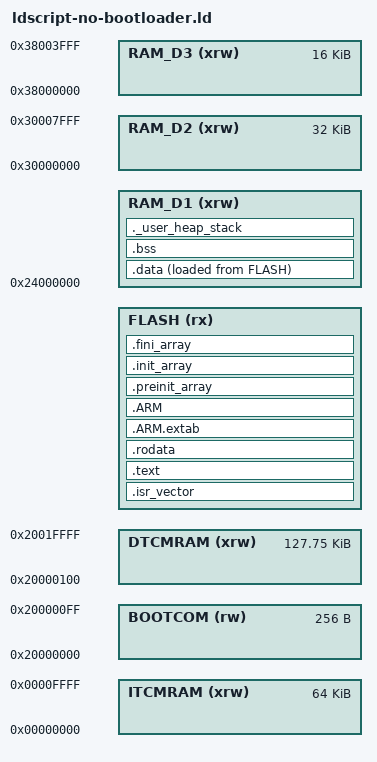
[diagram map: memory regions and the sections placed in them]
/*
******************************************************************************
**
**  Linker script for STM32H723ZGT6 (MicroNodePlus) -- standalone (no bootloader).
**
**  FLASH starts at 0x08000000 -- the application IS the only firmware on the
**  chip. BOOTCOM region (0x20000000, 256 B) is reserved in DTCMRAM so the
**  IPC layout matches the bootloader-aware build; an app linked here can be
**  re-built against `ldscript.ld` later without changing its source.
**
*****************************************************************************
*/

ENTRY(Reset_Handler)

_estack = ORIGIN(RAM_D1) + LENGTH(RAM_D1);
_Min_Heap_Size = 0x200;
_Min_Stack_Size = 0x400;

MEMORY
{
  ITCMRAM (xrw)    : ORIGIN = 0x00000000, LENGTH = 64K
  BOOTCOM (rw)     : ORIGIN = 0x20000000, LENGTH = 0x100
  DTCMRAM (xrw)    : ORIGIN = 0x20000100, LENGTH = 128K - 0x100
  FLASH    (rx)    : ORIGIN = 0x08000000 + LD_FLASH_OFFSET, LENGTH = LD_MAX_SIZE - LD_FLASH_OFFSET
  RAM_D1  (xrw)    : ORIGIN = 0x24000000, LENGTH = LD_MAX_DATA_SIZE
  RAM_D2  (xrw)    : ORIGIN = 0x30000000, LENGTH = 32K
  RAM_D3  (xrw)    : ORIGIN = 0x38000000, LENGTH = 16K
}

SECTIONS
{
  .isr_vector :
  {
    . = ALIGN(4);
    KEEP(*(.isr_vector))
    . = ALIGN(4);
  } >FLASH

  .text :
  {
    . = ALIGN(4);
    *(.text)
    *(.text*)
    *(.glue_7)
    *(.glue_7t)
    *(.eh_frame)

    KEEP (*(.init))
    KEEP (*(.fini))

    . = ALIGN(4);
    _etext = .;
  } >FLASH

  .rodata :
  {
    . = ALIGN(4);
    *(.rodata)
    *(.rodata*)
    . = ALIGN(4);
  } >FLASH

  .ARM.extab   : { *(.ARM.extab* .gnu.linkonce.armextab.*) } >FLASH
  .ARM (READONLY) : {
    __exidx_start = .;
    *(.ARM.exidx*)
    __exidx_end = .;
  } >FLASH

  .preinit_array (READONLY) :
  {
    PROVIDE_HIDDEN (__preinit_array_start = .);
    KEEP (*(.preinit_array*))
    PROVIDE_HIDDEN (__preinit_array_end = .);
  } >FLASH

  .init_array (READONLY) :
  {
    PROVIDE_HIDDEN (__init_array_start = .);
    KEEP (*(SORT(.init_array.*)))
    KEEP (*(.init_array*))
    PROVIDE_HIDDEN (__init_array_end = .);
  } >FLASH

  .fini_array (READONLY) :
  {
    PROVIDE_HIDDEN (__fini_array_start = .);
    KEEP (*(SORT(.fini_array.*)))
    KEEP (*(.fini_array*))
    PROVIDE_HIDDEN (__fini_array_end = .);
  } >FLASH

  _sidata = LOADADDR(.data);

  .data :
  {
    . = ALIGN(4);
    _sdata = .;
    *(.data)
    *(.data*)
    *(.RamFunc)
    *(.RamFunc*)
    . = ALIGN(4);
    _edata = .;
  } >RAM_D1 AT> FLASH

  . = ALIGN(4);
  .bss :
  {
    _sbss = .;
    __bss_start__ = _sbss;
    *(.bss)
    *(.bss*)
    *(COMMON)

    . = ALIGN(4);
    _ebss = .;
    __bss_end__ = _ebss;
  } >RAM_D1

  ._user_heap_stack :
  {
    . = ALIGN(8);
    PROVIDE ( end = . );
    PROVIDE ( _end = . );
    . = . + _Min_Heap_Size;
    . = . + _Min_Stack_Size;
    . = ALIGN(8);
  } >RAM_D1

  /DISCARD/ :
  {
    libc.a ( * )
    libm.a ( * )
    libgcc.a ( * )
  }

  .ARM.attributes 0 : { *(.ARM.attributes) }
}
